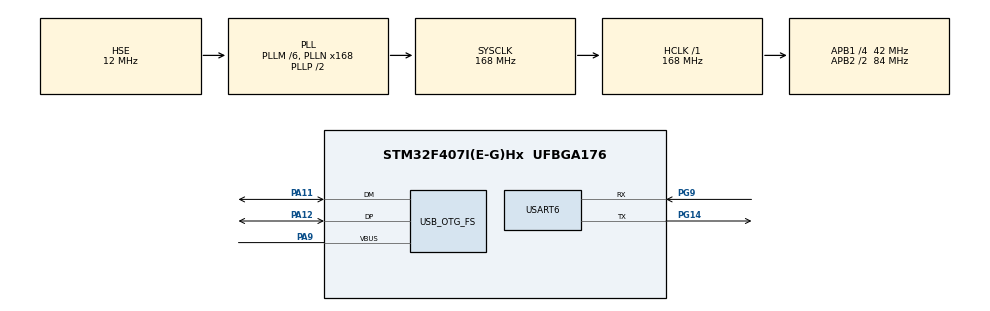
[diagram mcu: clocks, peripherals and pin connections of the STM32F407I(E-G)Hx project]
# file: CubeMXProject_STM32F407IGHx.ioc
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FREERTOS.Tasks01=defaultTask,24,128,StartDefaultTask,Default,NULL,Static,defaultTaskBuffer,defaultTaskControlBlock
FREERTOS.configENABLE_FPU=1
Mcu.Family=STM32F4
Mcu.Name=STM32F407I(E-G)Hx
Mcu.Package=UFBGA176
NVIC.OTG_FS_IRQn=true\:5\:0\:false\:false\:true\:true\:false\:true\:true
NVIC.PriorityGroup=NVIC_PRIORITYGROUP_4
NVIC.TIM6_DAC_IRQn=true\:15\:0\:false\:false\:true\:false\:false\:true\:true
NVIC.TimeBase=TIM6_DAC_IRQn
NVIC.TimeBaseIP=TIM6
PA11.Mode=Device_Only
PA11.Signal=USB_OTG_FS_DM
PA12.Mode=Device_Only
PA12.Signal=USB_OTG_FS_DP
PA13.Mode=Serial_Wire
PA13.Signal=SYS_JTMS-SWDIO
PA14.Mode=Serial_Wire
PA14.Signal=SYS_JTCK-SWCLK
PA9.Mode=Activate_VBUS
PA9.Signal=USB_OTG_FS_VBUS
PG14.Mode=Asynchronous
PG14.Signal=USART6_TX
PG9.Mode=Asynchronous
PG9.Signal=USART6_RX
PH0-OSC_IN.Mode=HSE-External-Oscillator
PH0-OSC_IN.Signal=RCC_OSC_IN
PH1-OSC_OUT.Mode=HSE-External-Oscillator
PH1-OSC_OUT.Signal=RCC_OSC_OUT
ProjectManager.HeapSize=0x200
ProjectManager.StackSize=0x400
ProjectManager.TargetToolchain=Makefile
RCC.48MHZClocksFreq_Value=48000000
RCC.AHBFreq_Value=168000000
RCC.APB1CLKDivider=RCC_HCLK_DIV4
RCC.APB1Freq_Value=42000000
RCC.APB1TimFreq_Value=84000000
RCC.APB2CLKDivider=RCC_HCLK_DIV2
RCC.APB2Freq_Value=84000000
RCC.APB2TimFreq_Value=168000000
RCC.CortexFreq_Value=168000000
RCC.HCLKFreq_Value=168000000
RCC.HSE_VALUE=12000000
RCC.HSI_VALUE=16000000
RCC.LSE_VALUE=32768
RCC.PLLM=6
RCC.PLLN=168
RCC.PLLQ=7
RCC.SYSCLKFreq_VALUE=168000000
RCC.SYSCLKSource=RCC_SYSCLKSOURCE_PLLCLK
RCC.VCOOutputFreq_Value=336000000
USART6.VirtualMode=VM_ASYNC
USB_DEVICE.APP_RX_DATA_SIZE-CDC_FS=64
USB_DEVICE.APP_TX_DATA_SIZE-CDC_FS=64
USB_DEVICE.CLASS_NAME_FS=CDC
USB_DEVICE.MANUFACTURER_STRING-CDC_FS=CUHK-SZ
USB_DEVICE.VirtualMode-CDC_FS=Cdc
USB_DEVICE.VirtualModeFS=Cdc_FS
USB_OTG_FS.VirtualMode=Device_Only
VP_FREERTOS_VS_CMSIS_V2.Mode=CMSIS_V2
VP_SYS_VS_tim6.Mode=TIM6
VP_USB_DEVICE_VS_USB_DEVICE_CDC_FS.Mode=CDC_FS
board=custom

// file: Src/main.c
/* USER CODE BEGIN Header */
/**
  ******************************************************************************
  * @file           : main.c
  * @brief          : Main program body
  ******************************************************************************
  * @attention
  *
  * Copyright (c) 2026 STMicroelectronics.
  * All rights reserved.
  *
  * This software is licensed under terms that can be found in the LICENSE file
  * in the root directory of this software component.
  * If no LICENSE file comes with this software, it is provided AS-IS.
  *
  ******************************************************************************
  */
/* USER CODE END Header */
#include "main.h"
#include "cmsis_os.h"
#include "usart.h"
#include "usb_device.h"
#include "gpio.h"

/* USER CODE BEGIN Includes */
#include "bsp_hooks/general.h"
/* USER CODE END Includes */

void SystemClock_Config(void);
void MX_FREERTOS_Init(void);

int main(void)
{

  /* MCU Configuration--------------------------------------------------------*/

  /* Reset of all peripherals, Initializes the Flash interface and the Systick. */
  HAL_Init();

  /* Configure the system clock */
  SystemClock_Config();

  /* Initialize all configured peripherals */
  MX_GPIO_Init();
  MX_USART6_UART_Init();
  /* USER CODE BEGIN 2 */
  bsp_init_before_rtos_init();
  /* USER CODE END 2 */

  /* Init scheduler */
  osKernelInitialize();  /* Call init function for freertos objects (in cmsis_os2.c) */
  MX_FREERTOS_Init();

  /* Start scheduler */
  osKernelStart();

  /* We should never get here as control is now taken by the scheduler */

  /* Infinite loop */
  while (1)
  {

  }
}

void SystemClock_Config(void)
{
  RCC_OscInitTypeDef RCC_OscInitStruct = {0};
  RCC_ClkInitTypeDef RCC_ClkInitStruct = {0};

  /** Configure the main internal regulator output voltage
  */
  __HAL_RCC_PWR_CLK_ENABLE();
  __HAL_PWR_VOLTAGESCALING_CONFIG(PWR_REGULATOR_VOLTAGE_SCALE1);

  /** Initializes the RCC Oscillators according to the specified parameters
  * in the RCC_OscInitTypeDef structure.
  */
  RCC_OscInitStruct.OscillatorType = RCC_OSCILLATORTYPE_HSE;
  RCC_OscInitStruct.HSEState = RCC_HSE_ON;
  RCC_OscInitStruct.PLL.PLLState = RCC_PLL_ON;
  RCC_OscInitStruct.PLL.PLLSource = RCC_PLLSOURCE_HSE;
  RCC_OscInitStruct.PLL.PLLM = 6;
  RCC_OscInitStruct.PLL.PLLN = 168;
  RCC_OscInitStruct.PLL.PLLP = RCC_PLLP_DIV2;
  RCC_OscInitStruct.PLL.PLLQ = 7;
  if (HAL_RCC_OscConfig(&RCC_OscInitStruct) != HAL_OK)
  {
    Error_Handler();
  }

  /** Initializes the CPU, AHB and APB buses clocks
  */
  RCC_ClkInitStruct.ClockType = RCC_CLOCKTYPE_HCLK|RCC_CLOCKTYPE_SYSCLK
                              |RCC_CLOCKTYPE_PCLK1|RCC_CLOCKTYPE_PCLK2;
  RCC_ClkInitStruct.SYSCLKSource = RCC_SYSCLKSOURCE_PLLCLK;
  RCC_ClkInitStruct.AHBCLKDivider = RCC_SYSCLK_DIV1;
  RCC_ClkInitStruct.APB1CLKDivider = RCC_HCLK_DIV4;
  RCC_ClkInitStruct.APB2CLKDivider = RCC_HCLK_DIV2;

  if (HAL_RCC_ClockConfig(&RCC_ClkInitStruct, FLASH_LATENCY_5) != HAL_OK)
  {
    Error_Handler();
  }
}

void HAL_TIM_PeriodElapsedCallback(TIM_HandleTypeDef *htim)
{
  if (htim->Instance == TIM6)
  {
    HAL_IncTick();
  }
}

void Error_Handler(void)
{
  /* USER CODE BEGIN Error_Handler_Debug */
  bsp_error_handler();
  /* USER CODE END Error_Handler_Debug */
}
#ifdef USE_FULL_ASSERT
/**
  * @brief  Reports the name of the source file and the source line number
  *         where the assert_param error has occurred.
  * @param  file: pointer to the source file name
  * @param  line: assert_param error line source number
  * @retval None
  */
void assert_failed(uint8_t *file, uint32_t line)
{
  /* USER CODE BEGIN 6 */
  bsp_assert_failed(file, line);
  /* USER CODE END 6 */
}
#endif /* USE_FULL_ASSERT */

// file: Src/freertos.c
/* USER CODE BEGIN Header */
/**
  ******************************************************************************
  * File Name          : freertos.c
  * Description        : Code for freertos applications
  ******************************************************************************
  * @attention
  *
  * Copyright (c) 2026 STMicroelectronics.
  * All rights reserved.
  *
  * This software is licensed under terms that can be found in the LICENSE file
  * in the root directory of this software component.
  * If no LICENSE file comes with this software, it is provided AS-IS.
  *
  ******************************************************************************
  */
/* USER CODE END Header */

#include "FreeRTOS.h"
#include "task.h"
#include "main.h"
#include "cmsis_os.h"

/* USER CODE BEGIN Includes */
#include "bsp_hooks/general.h"
/* USER CODE END Includes */

typedef StaticTask_t osStaticThreadDef_t;

/* Definitions for defaultTask */
osThreadId_t defaultTaskHandle;
uint32_t defaultTaskBuffer[ 128 ];
osStaticThreadDef_t defaultTaskControlBlock;
const osThreadAttr_t defaultTask_attributes = {
  .name = "defaultTask",
  .cb_mem = &defaultTaskControlBlock,
  .cb_size = sizeof(defaultTaskControlBlock),
  .stack_mem = &defaultTaskBuffer[0],
  .stack_size = sizeof(defaultTaskBuffer),
  .priority = (osPriority_t) osPriorityNormal,
};

void StartDefaultTask(void *argument);

extern void MX_USB_DEVICE_Init(void);
void MX_FREERTOS_Init(void); /* (MISRA C 2004 rule 8.1) */

void MX_FREERTOS_Init(void) {
  /* USER CODE BEGIN Init */
  bsp_init_after_rtos_init();
  /* USER CODE END Init */

  /* Create the thread(s) */
  /* creation of defaultTask */
  defaultTaskHandle = osThreadNew(StartDefaultTask, NULL, &defaultTask_attributes);

}

void StartDefaultTask(void *argument)
{
  /* init code for USB_DEVICE */
  MX_USB_DEVICE_Init();
  /* USER CODE BEGIN StartDefaultTask */
  bsp_init_in_rtos_thread();

  // 这个默认任务是 CubeMX 自动生成的
  // CubeMX 会用它来做一些初始化工作（比如 USB 设备），但我们不需要它一直运行，所以在这里直接删除它
  osThreadTerminate(defaultTaskHandle);
  /* USER CODE END StartDefaultTask */
}
